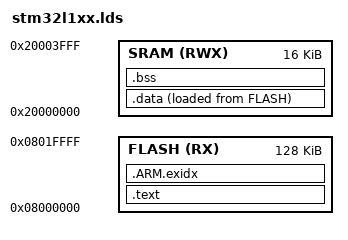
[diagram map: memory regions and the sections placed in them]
/*
 * Copyright 2013 OpenMote Technologies, S.L.
 */

/**
 * Indicate the architecture and format
 */
OUTPUT_ARCH(arm)
OUTPUT_FORMAT("elf32-littlearm", "elf32-littlearm", "elf32-littlearm")

/**
 * Indicate to the linker the entry point.
 */
ENTRY(Reset_Handler)

/**
 * Linker script for ST STM32L151RBT6 (16K RAM, 128K Flash)
 */
MEMORY
{
    FLASH (RX) : ORIGIN = 0x08000000, LENGTH = 128K
    SRAM (RWX) : ORIGIN = 0x20000000, LENGTH = 16K
}

SECTIONS
{
    .text :
    {
        _text = .;
        . = ALIGN(4);
        KEEP(*(.vectors))

        . = ALIGN(4);
        *(.text*)
        *(.rodata*)
        
        . = ALIGN(4);
        KEEP(*(.init))
        
        . = ALIGN(4);
        __preinit_array_start = .;
        KEEP (*(.preinit_array))
        __preinit_array_end = .;

        . = ALIGN(4);
        __init_array_start = .;
        KEEP (*(SORT(.init_array.*)))
        KEEP (*(.init_array))
        __init_array_end = .;

        . = ALIGN(4);
        KEEP (*crtbegin.o(.ctors))
        KEEP (*(EXCLUDE_FILE (*crtend.o) .ctors))
        KEEP (*(SORT(.ctors.*)))
        KEEP (*crtend.o(.ctors))

        . = ALIGN(4);
        KEEP(*(.fini))

        . = ALIGN(4);
        __fini_array_start = .;
        KEEP (*(.fini_array))
        KEEP (*(SORT(.fini_array.*)))
        __fini_array_end = .;

        . = ALIGN(4);
        KEEP (*crtbegin.o(.dtors))
        KEEP (*(EXCLUDE_FILE (*crtend.o) .dtors))
        KEEP (*(SORT(.dtors.*)))
        KEEP (*crtend.o(.dtors))
        
        _etext = .;
    } > FLASH= 0

    .data :
    {
        . = ALIGN(4);
        _data = .;
        *(.data)
        *(.data*)
        _edata = .;
    } > SRAM AT > FLASH

    .ARM.exidx :
    {
        . = ALIGN(4);
        *(.ARM.exidx*)
    } > FLASH

    .bss :
    {
        . = ALIGN(4);
        _bss = .;
        *(.bss*)
        *(COMMON)
        _ebss = .;
    } > SRAM
    
    /DISCARD/ :
    {
        libc.a ( * )
        libm.a ( * )
        libgcc.a ( * )
    }
}
